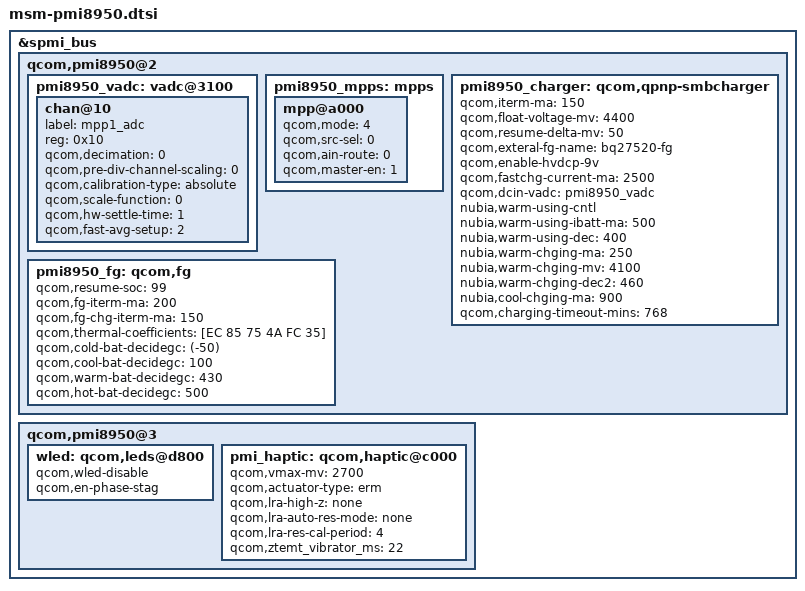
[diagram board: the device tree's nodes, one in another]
/* Copyright (c) 2015-2016, The Linux Foundation. All rights reserved.
 *
 * This program is free software; you can redistribute it and/or modify
 * it under the terms of the GNU General Public License version 2 and
 * only version 2 as published by the Free Software Foundation.
 *
 * This program is distributed in the hope that it will be useful,
 * but WITHOUT ANY WARRANTY; without even the implied warranty of
 * MERCHANTABILITY or FITNESS FOR A PARTICULAR PURPOSE.  See the
 * GNU General Public License for more details.
 */

#include <dt-bindings/msm/power-on.h>

&spmi_bus {

	qcom,pmi8950@2 {

		pmi8950_vadc: vadc@3100 {
			//CONFIG_NUBIA_WEIPU_CHARGER add for usb ntc temperature detect 
			chan@10 {  
				label = "mpp1_adc";  
				reg = <0x10>;             // channel for MPP1,max 1.8V,scale 1:1
				qcom,decimation = <0>;    //sampling rate, 0 for 512(default)
				qcom,pre-div-channel-scaling = <0>; //0 for 1:1 scaling 
				qcom,calibration-type = "absolute";  
				qcom,scale-function = <0>;    
				qcom,hw-settle-time = <1>;   //delay time before rd ADC, 1 for 100us 
				qcom,fast-avg-setup = <2>;   //average num of samples, 2 for 4
			};
		    //NUBIA_WEIPU end
		};

		pmi8950_mpps: mpps {
			mpp@a000 {
				//CONFIG_NUBIA_WEIPU_CHARGER add for usb ntc temperature detect
				qcom,mode = <4>; // A-input  QPNP_PIN_MODE_AIN
				qcom,src-sel = <0>; //MPP Constant  QPNP_PIN_SEL_FUNC_CONSTANT
				qcom,ain-route = <0>; // QPNP_PIN_AIN_AMUX_CH5 = 0 for MPP1
				qcom,master-en = <1>; //Enable MPP 
				status = "okay";
				//NUBIA_WEIPU end
			};

		};

		pmi8950_charger: qcom,qpnp-smbcharger {
			qcom,iterm-ma = <150>;            //Nubia Modify 100 to 150
			qcom,float-voltage-mv = <4400>;   //Nubia Modify 4200 to 4400
			qcom,resume-delta-mv = <50>;      //Nubia Modify 200 to 50
			/delete-property/ qcom,chg-inhibit-fg;			  //Nubia Marked
			qcom,exteral-fg-name = "bq27520-fg";
			//Nubia add
			qcom,enable-hvdcp-9v;
			qcom,fastchg-current-ma = <2500>;
			qcom,dcin-vadc = <&pmi8950_vadc>;

			nubia,warm-using-cntl;
			nubia,warm-using-ibatt-ma = <500>;
			nubia,warm-using-dec = <400>;
			nubia,warm-chging-ma = <250>;
			nubia,warm-chging-mv = <4100>;
			nubia,warm-chging-dec2 = <460>;
			nubia,cool-chging-ma = <900>;
			
			qcom,charging-timeout-mins = <768>;
			//Nubia end
			
		};

		pmi8950_fg: qcom,fg {
			qcom,resume-soc = <99>;
			qcom,fg-iterm-ma = <200>;            //Nubia Modify 150 to 200
			qcom,fg-chg-iterm-ma = <150>;        //Nubia Modify 100 to 150
			//Nubia add
			qcom,thermal-coefficients = [EC 85 75 4A FC 35];
			qcom,cold-bat-decidegc = <(-50)>;
			qcom,cool-bat-decidegc = <100>;
			qcom,warm-bat-decidegc = <430>;
			qcom,hot-bat-decidegc = <500>;
			//Nubia end

		};

	};

	qcom,pmi8950@3 {
		wled: qcom,leds@d800 {
			qcom,wled-disable;
			qcom,en-phase-stag;
			/delete-property/ qcom,led-strings-list;
		};

		pmi_haptic: qcom,haptic@c000 {
			qcom,vmax-mv = <2700>;
			status="okay";
			qcom,actuator-type = "erm";
			qcom,lra-high-z = "none";
			qcom,lra-auto-res-mode = "none";
			qcom,lra-res-cal-period = <4>;
			qcom,ztemt_vibrator_ms =<22>;
		};
	};
};
